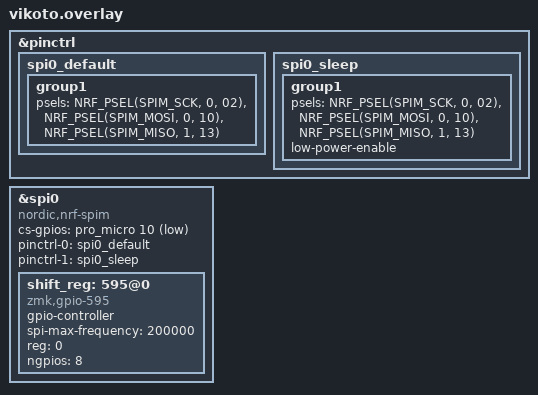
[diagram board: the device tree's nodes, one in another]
#include <dt-bindings/led/led.h>

&pinctrl {
    spi0_default: spi0_default {
        group1 {
            psels = <NRF_PSEL(SPIM_SCK, 0, 02)>,
                <NRF_PSEL(SPIM_MOSI, 0, 10)>,
                <NRF_PSEL(SPIM_MISO, 1, 13)>;
        };
    };

    spi0_sleep: spi0_sleep {
        group1 {
            psels = <NRF_PSEL(SPIM_SCK, 0, 02)>,
                <NRF_PSEL(SPIM_MOSI, 0, 10)>,
                <NRF_PSEL(SPIM_MISO, 1, 13)>;
            low-power-enable;
        };
    };
    
    /**
    * Vikoto not allowed to use RGB until I clean up vikoto-pinctrl.dtsi to not use i2c1 for vik
    spi1_default: spi1_default {
        group1 {
            psels = <NRF_PSEL(SPIM_MOSI, 0, 6)
                     NRF_PSEL(SPIM_SCK, 1, 1)
                     NRF_PSEL(SPIM_MISO, 1, 3)>;
        };
    };

    spi1_sleep: spi1_sleep {
        group1 {
            psels = <NRF_PSEL(SPIM_MOSI, 0, 6)
                     NRF_PSEL(SPIM_SCK, 1, 1)
                     NRF_PSEL(SPIM_MISO, 1, 3)>;
            low-power-enable;
        };
    };
    */
};

&spi0 {
    compatible = "nordic,nrf-spim";
    /* Cannot be used together with i2c0. */
    status = "okay";
    cs-gpios = <&pro_micro 10 GPIO_ACTIVE_LOW>;
    pinctrl-0 = <&spi0_default>;
    pinctrl-1 = <&spi0_sleep>;
    pinctrl-names = "default", "sleep";

    shift_reg: 595@0 {
        compatible = "zmk,gpio-595";
        status = "okay";
        gpio-controller;
        spi-max-frequency = <200000>;
        reg = <0>;
        #gpio-cells = <2>;
        ngpios = <8>;
    };
};

/**
 * Vikoto not allowed to use RGB until I clean up vikoto-pinctrl.dtsi to not use i2c1 for vik
&spi1 {
    compatible = "nordic,nrf-spim";
    // Cannot be used together with i2c1.
    status = "okay";
    cs-gpios = <&pro_micro 1 GPIO_ACTIVE_LOW>;
    pinctrl-0 = <&spi1_default>;
    pinctrl-1 = <&spi1_sleep>;
    pinctrl-names = "default", "sleep";


    led_strip: ws2812@0 {
        compatible = "worldsemi,ws2812-spi";

        // SPI
        reg = <0>; // ignored, but necessary for SPI bindings
        spi-max-frequency = <4000000>;

        // WS2812
        chain-length = <42>;
        spi-one-frame = <0x70>;
        spi-zero-frame = <0x40>;
        color-mapping = <LED_COLOR_ID_GREEN
                         LED_COLOR_ID_RED
                         LED_COLOR_ID_BLUE>;
    };
};

/ {
    chosen {
        zmk,underglow = &led_strip;
    };
};
*/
